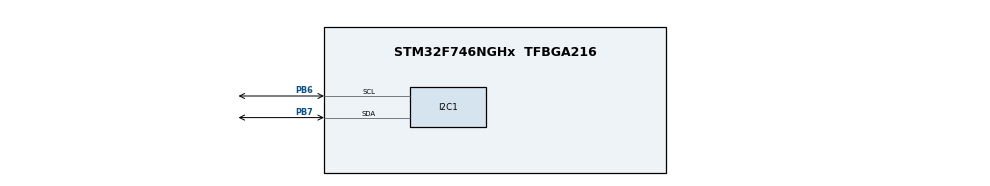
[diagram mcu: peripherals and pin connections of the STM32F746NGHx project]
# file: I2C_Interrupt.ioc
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I2C1.Timing=0x20404768
Mcu.Family=STM32F7
Mcu.Name=STM32F746NGHx
Mcu.Package=TFBGA216
NVIC.PriorityGroup=NVIC_PRIORITYGROUP_4
PB6.GPIO_Pu=GPIO_PULLUP
PB6.Mode=I2C
PB6.Signal=I2C1_SCL
PB7.GPIO_Pu=GPIO_PULLUP
PB7.Mode=I2C
PB7.Signal=I2C1_SDA
PC14/OSC32_IN.Mode=LSE-External-Oscillator
PC14/OSC32_IN.Signal=RCC_OSC32_IN
PC15/OSC32_OUT.Mode=LSE-External-Oscillator
PC15/OSC32_OUT.Signal=RCC_OSC32_OUT
PH0/OSC_IN.Mode=HSE-External-Oscillator
PH0/OSC_IN.Signal=RCC_OSC_IN
PH1/OSC_OUT.Mode=HSE-External-Oscillator
PH1/OSC_OUT.Signal=RCC_OSC_OUT
ProjectManager.HeapSize=0x200
ProjectManager.StackSize=0x400
ProjectManager.TargetToolchain=STM32CubeIDE
RCC.AHBFreq_Value=216000000
RCC.APB1CLKDivider=RCC_HCLK_DIV4
RCC.APB1Freq_Value=54000000
RCC.APB1TimFreq_Value=108000000
RCC.APB2CLKDivider=RCC_HCLK_DIV2
RCC.APB2Freq_Value=108000000
RCC.APB2TimFreq_Value=216000000
RCC.CortexFreq_Value=216000000
RCC.HCLKFreq_Value=216000000
RCC.HSE_VALUE=25000000
RCC.HSI_VALUE=16000000
RCC.PLL48CLockSelection=RCC_CLK48SOURCE_PLLSAIP
RCC.PLLI2SN=100
RCC.PLLM=8
RCC.PLLN=216
RCC.PLLQ=9
RCC.PLLSAIN=384
RCC.PLLSAIP=RCC_PLLSAIP_DIV8
RCC.PLLSAIR=5
RCC.PLLSAIRDiv=RCC_PLLSAIDIVR_8
RCC.SDMMCClockSelection=RCC_SDMMC1CLKSOURCE_CLK48
RCC.SYSCLKFreq_VALUE=216000000
RCC.SYSCLKSource=RCC_SYSCLKSOURCE_PLLCLK
RCC.USBFreq_Value=96000000
RCC.VCOOutputFreq_Value=432000000
board=STM32F746G-DISCO

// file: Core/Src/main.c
/* USER CODE BEGIN Header */
/**
  ******************************************************************************
  * @file           : main.c
  * @brief          : Main program body
  ******************************************************************************
  * @attention
  *
  * Copyright (c) 2025 STMicroelectronics.
  * All rights reserved.
  *
  * This software is licensed under terms that can be found in the LICENSE file
  * in the root directory of this software component.
  * If no LICENSE file comes with this software, it is provided AS-IS.
  *
  ******************************************************************************
  */
/* USER CODE END Header */
#include "main.h"
#include<string.h>
#include "stm32f7xx.h"
/* USER CODE BEGIN Includes */
#define EEPROM_I2C_ADDR     (0xA2) // 0x51 << 1, 8-bit address
#define EEPROM_MEM_ADDR     0x00
#define EEPROM_TIMEOUT      100
/* USER CODE END Includes */

I2C_HandleTypeDef hi2c1;

/* USER CODE BEGIN PV */
uint8_t writeData[] = "Param";
uint8_t readData[sizeof(writeData)] = {0};

volatile uint8_t i2cWriteComplete = 0;
volatile uint8_t i2cReadComplete = 0;
/* USER CODE END PV */

void SystemClock_Config(void);
static void MX_GPIO_Init(void);
static void MX_I2C1_Init(void);

int main(void)
{

  /* MCU Configuration--------------------------------------------------------*/

  /* Reset of all peripherals, Initializes the Flash interface and the Systick. */
  HAL_Init();

  /* Configure the system clock */
  SystemClock_Config();

  /* Initialize all configured peripherals */
  MX_GPIO_Init();
  MX_I2C1_Init();
  /* USER CODE BEGIN 2 */
  HAL_NVIC_SetPriority(I2C1_EV_IRQn, 0, 0);
    HAL_NVIC_EnableIRQ(I2C1_EV_IRQn);

    /* Start I2C EEPROM Write (Interrupt) */
    HAL_I2C_Mem_Write_IT(&hi2c1, EEPROM_I2C_ADDR, EEPROM_MEM_ADDR,
                         I2C_MEMADD_SIZE_8BIT, writeData, sizeof(writeData));

    /* Wait for write complete */
    while (!i2cWriteComplete);

    HAL_Delay(5); // EEPROM internal write cycle time (typically 5ms)

    /* Start I2C EEPROM Read (Interrupt) */
    HAL_I2C_Mem_Read_IT(&hi2c1, EEPROM_I2C_ADDR, EEPROM_MEM_ADDR,
                        I2C_MEMADD_SIZE_8BIT, readData, sizeof(readData));

    /* Wait for read complete */
    while (!i2cReadComplete);

    if (memcmp(writeData, readData, sizeof(writeData)) == 0)
      {
        // Data match: Successful read
      }
      else
      {
        // Data mismatch: Handle error
      }

  /* USER CODE END 2 */

  /* Infinite loop */
  while (1)
  {

  }
}
void HAL_I2C_MemTxCpltCallback(I2C_HandleTypeDef *hi2c)
{
  if (hi2c->Instance == I2C1)
    i2cWriteComplete = 1;
}

/* I2C Read Complete Callback */
void HAL_I2C_MemRxCpltCallback(I2C_HandleTypeDef *hi2c)
{
  if (hi2c->Instance == I2C1)
    i2cReadComplete = 1;
}

/* I2C Error Callback */
void HAL_I2C_ErrorCallback(I2C_HandleTypeDef *hi2c)
{
  // Optional: handle I2C errors
}

/* I2C IRQ Handler */
void I2C1_EV_IRQHandler(void)
{
  HAL_I2C_EV_IRQHandler(&hi2c1);
}
void SystemClock_Config(void)
{
    RCC->CR |= RCC_CR_HSEON;
    while (!(RCC->CR & RCC_CR_HSERDY));

    // Power and overdrive
    RCC->APB1ENR |= RCC_APB1ENR_PWREN;
    PWR->CR1 |= PWR_CR1_ODEN;
    while (!(PWR->CSR1 & PWR_CSR1_ODRDY));
    PWR->CR1 |= PWR_CR1_ODSWEN;
    while (!(PWR->CSR1 & PWR_CSR1_ODSWRDY));

    FLASH->ACR = FLASH_ACR_LATENCY_7WS;

    // PLL config: HSE = 25MHz -> VCO = 1080MHz -> SYSCLK = 216MHz
    RCC->PLLCFGR = (25 << RCC_PLLCFGR_PLLM_Pos) |
                   (432 << RCC_PLLCFGR_PLLN_Pos) |
                   (0 << RCC_PLLCFGR_PLLP_Pos) |  // PLLP = /2
                   (RCC_PLLCFGR_PLLSRC_HSE) |
                   (9 << RCC_PLLCFGR_PLLQ_Pos);

    RCC->CR |= RCC_CR_PLLON;
    while (!(RCC->CR & RCC_CR_PLLRDY));

    RCC->CFGR |= RCC_CFGR_SW_PLL;
    while ((RCC->CFGR & RCC_CFGR_SWS_Msk) != RCC_CFGR_SWS_PLL);

    RCC->CFGR |= RCC_CFGR_HPRE_DIV1;
    RCC->CFGR |= RCC_CFGR_PPRE1_DIV4;
    RCC->CFGR |= RCC_CFGR_PPRE2_DIV2;
}

static void MX_I2C1_Init(void)
{

  hi2c1.Instance = I2C1;
  hi2c1.Init.Timing = 0x20404768;
  hi2c1.Init.OwnAddress1 = 0;
  hi2c1.Init.AddressingMode = I2C_ADDRESSINGMODE_7BIT;
  hi2c1.Init.DualAddressMode = I2C_DUALADDRESS_DISABLE;
  hi2c1.Init.OwnAddress2 = 0;
  hi2c1.Init.OwnAddress2Masks = I2C_OA2_NOMASK;
  hi2c1.Init.GeneralCallMode = I2C_GENERALCALL_DISABLE;
  hi2c1.Init.NoStretchMode = I2C_NOSTRETCH_DISABLE;
  if (HAL_I2C_Init(&hi2c1) != HAL_OK)
  {
    Error_Handler();
  }

  /** Configure Analogue filter
  */
  if (HAL_I2CEx_ConfigAnalogFilter(&hi2c1, I2C_ANALOGFILTER_ENABLE) != HAL_OK)
  {
    Error_Handler();
  }

  /** Configure Digital filter
  */
  if (HAL_I2CEx_ConfigDigitalFilter(&hi2c1, 0) != HAL_OK)
  {
    Error_Handler();
  }

}

static void MX_GPIO_Init(void)
{

  /* GPIO Ports Clock Enable */
  __HAL_RCC_GPIOB_CLK_ENABLE();
  __HAL_RCC_GPIOC_CLK_ENABLE();
  __HAL_RCC_GPIOH_CLK_ENABLE();

}

void Error_Handler(void)
{
  __disable_irq();
  while (1)
  {
  }
}
